# dm646x_cslr_vpif register map
Vendor: Texas Instruments
Peripheral module from a debugger description file.
Registers are 32-bit, access not given, reset 0x0 unless marked. A register's access mark holds for its fields unless they carry their own. Offsets are as the file gives them; lines under a group give offsets from that group; [hi:lo] are bit positions; {n}, {i} and the like mark numbered series; 'fields as' and 'values as' point back to an identical list; <NAME> marks a mode.

## VPIF
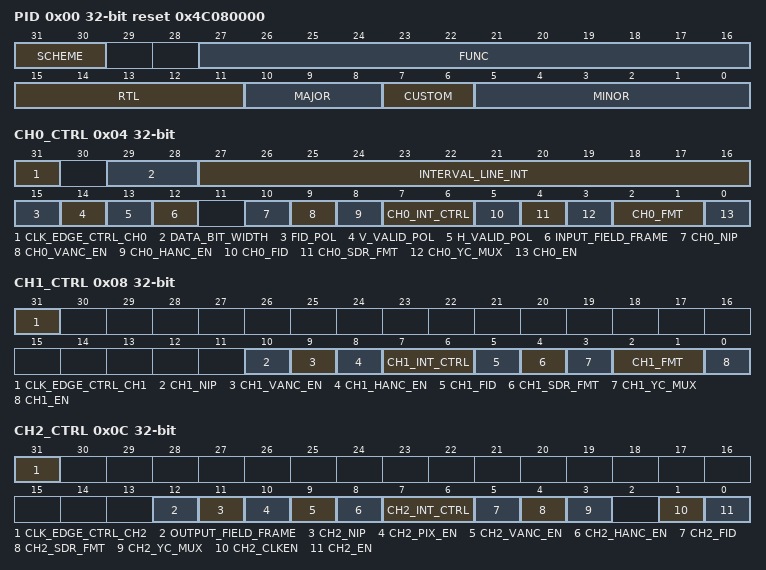
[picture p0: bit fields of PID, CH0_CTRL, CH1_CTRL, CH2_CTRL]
0x00 PID reset 0x4C080000 — VPIF Identification
  [31:30] SCHEME ro — Used to distinguish between old scheme and current. Spare bit to encode future schemes. Fixed to be "01"
  [27:16] FUNC ro — Function indicates an S/W compatible module family. If there is not level of S/W compatibility, a new Func number (and hence PID) should be assigned
  [15:11] RTL ro — Indicates RTL version
  [10:8] MAJOR ro — Local revision number which should be owned by module designer. This number should be updated for each major design change (such as bug fix, and memory size change etc ). In present design, fixed to be 0
  [7:6] CUSTOM ro — Indicates a special version for a particular device. Consequence of use may avoid use of standard chip support library (CSL). In this module, fixed to be 0.
  [5:0] MINOR ro — Local revision number which should be owned by module designer. This number should be updated for each small design change. In present design, fixed to be 0.
0x04 CH0_CTRL — Channel#0 control register
  [31] CLK_EDGE_CTRL_CH0 rw — This register defines timing relationship between data phase and clock edge for video input data which is connected to VPIF channel 0 (at the chip-pin level). Edge control is carried out outside the module (just register signal is only asserted from the module) 0: data phase is changed at rising edge of the input clock 1: data phase is changed at falling edge of the input clock
    0=RISE_EDGE (data phase is changed at rising edge of the input clock); 1=FALL_EDGE (data phase is changed at falling edge of the input clock)
  [29:28] DATA_BIT_WIDTH rw — Data bit width 00: 8 bit/pixel 01: 10 bit/pixel 10: 12 bit/pixel
  [27:16] INTERVAL_LINE_INT rw — Line interrrupt interval
  [15] FID_POL rw — Field ID polarity
    0=NOINVERT (No inversion); 1=INVERT (Invert incoming field ID signal inside the module)
  [14] V_VALID_POL rw — Vertical pixel valid signal polarity control
    0=NOINVERT (No inversion); 1=INVERT (Invert incoming "vertical pixel valid" signal inside the module)
  [13] H_VALID_POL rw — Horizontal pixel valid signal polarity control
    0=NOINVERT (No inversion); 1=INVERT (Invert incoming "horizontal pixel valid" signal inside the module)
  [12] INPUT_FIELD_FRAME rw — SDRAM storage mode of input picture
    0=FIELD (Field storage); 1=FRAME (Frame storage)
  [10] CH0_NIP rw — Output display format
    0=INTERLACED (Interlaced, 60 field/sec); 1=PROGRESS (Progressive, 30 frame/sec)
  [9] CH0_VANC_EN rw — Channel#0 Vertical Ancillary data enable 0:Vertical ancillary Data not supported 1:Vertical ancillary data is supported
    0=CH0_VRT_DIS (Vertical ancillary data disable); 1=CH0_VRT_EN (Vertical ancillary data enable)
  [8] CH0_HANC_EN rw — Channel#0 Horizontal Ancillary data enable 0: Horizontal ancillary Data not supported 1:Horizontal ancillary data is supported
    0=CH0_HZN_DIS (Horizontal ancillary data disable); 1=CH0_HZN_EN (Horizontal ancillary data enable)
  [7:6] CH0_INT_CTRL rw — Channel#0 Frame level interrupt to CPU 00: top field V-sync only 01: bottom field V-sync only 10: both top and bottom field V-sync 11: Reserved
  [5] CH0_FID ro — Channel#0 Field Identification
  [4] CH0_SDR_FMT rw — SDRAM address format control register 0: raster scanning mode 1: sub-picture mode
    0=CH0_RAS (Channel#0 Raster mode); 1=CH0_SP (Channel#0 sub-picture mode)
  [3] CH0_YC_MUX rw — Channel#0 input data format 0: Y/C non-multiplexed mode 1: Y/C multiplexed mode
    0=CH0_NON_YC (Channel#0 Non-multiplexed Y/C); 1=CH0_YC (Channel#0 Y/C multiplexed)
  [2:1] CH0_FMT rw — Channel#0 data mode to be processed 0x: BT. video (Y/C format) capture mode (sync signal is multiplexed). 1x: CCD/CMOS data capture mode (sync signal is independently prepared).
    0=BT_VIDEO_0 (BT. video (Y/C format) capture mode); 1=BT_VIDEO_1 (BT. video (Y/C format) capture mode); 2=CCD_CMOS_0 (CCD/CMOS data capture mode); 3=CCD_CMOS_1 (CCD/CMOS data capture mode)
  [0] CH0_EN rw — Channel#0 VPIF enable 0: Channel#0 VPIF module inactivated 1: Channel#0 VPIF module activated
    0=CH0_DIS (Channel#0 disable); 1=CH0_EN (Channel#0 enable)
0x08 CH1_CTRL — Channel#1 control register
  [31] CLK_EDGE_CTRL_CH1 rw — This register defines timing relationship between data phase and clock edge for video input data which is connected to VPIF channel 1 (at the chip-pin level). Edge control is carried out outside the module (just register signal is only asserted from the module) 0: data phase is changed at rising edge of the input clock 1: data phase is changed at falling edge of the input clock
    values as CH0_CTRL.CLK_EDGE_CTRL_CH0
  [10] CH1_NIP rw — Output display format 0: Interlaced (60 [field/sec]) format. 1: Progressive (30 [frame/sec]) format.
    values as CH0_CTRL.CH0_NIP
  [9] CH1_VANC_EN rw — Channel#1 Vertical Ancillary data enable 0: Vertical Ancillary Data not supported 1: Vertical ancillary data is supported
    0=CH1_VRT_DIS (Vertical ancillary data disable); 1=CH1_VRT_EN (Veritical ancillary data enable)
  [8] CH1_HANC_EN rw — Channel#1 Horizontal Ancillary data enable 0: Horizontal ancillary Data not supported 1:Horizontal ancillary data is supported
    0=CH1_HZN_DIS (Horizontal ancillary data disable); 1=CH1_HZN_EN (Horizontal ancillary data enable)
  [7:6] CH1_INT_CTRL rw — Channel#1 Frame level interrupt to CPU 00: top field V-sync only 01: bottom field V-sync only 10: both top and bottom field V-sync 11: Reserved
  [5] CH1_FID ro — Channel#1 Field Identification
  [4] CH1_SDR_FMT rw — SDRAM address format control register 0: raster scanning mode 1: sub-picture mode
    0=CH1_RAS (Channel#1 Raster mode); 1=CH1_SP (Channel#1 sub-picture mode)
  [3] CH1_YC_MUX rw — Channel#1 input data format 0: Y/C non-multiplexed mode 1: Y/C multiplexed mode
    0=CH1_NON_YC (Channel#1 Non-multiplexed Y/C); 1=CH1_YC (Channel#1 Y/C multiplexed)
  [2:1] CH1_FMT rw — Channel#1 data mode to be processed 0x: BT. video (Y/C format) capture mode (sync signal is multiplexed). 1x: CCD/CMOS data capture mode (sync signal is independently prepared).
    values as CH0_CTRL.CH0_FMT
  [0] CH1_EN rw — Channel#1 VPIF enable 0: Channel#1 VPIF module inactivated 1: Channel#1 VPIF module activated
    0=CH1_DIS (Channel#1 disable); 1=CH1_EN (Channel#1 enable)
0x0C CH2_CTRL — Channel#2 control register
  [31] CLK_EDGE_CTRL_CH2 rw — This register defines timing relationship between data phase and clock edge for video output data which is connected to VPIF channel 2 (at the chip-pin level). Edge control is carried out outside the module (just register signal is only asserted from the module) 0: data phase is changed at rising edge of the input clock 1: data phase is changed at falling edge of the input clock
    values as CH0_CTRL.CLK_EDGE_CTRL_CH0
  [12] OUTPUT_FIELD_FRAME rw — SDRAM storage mode of output picture 0: field independently stored. 1: frame based.
    0=FIELD (Field storage); 1=FRAME (Frame storage)
  [11] CH2_NIP rw — Output display format 0: Interlaced (60 [field/sec]) format. 1: Progressive (30 [frame/sec]) format.
    values as CH0_CTRL.CH0_NIP
  [10] CH2_PIX_EN rw — Pixel data enable or disable 0: Pixel data disabled 1: Pixel data enabled
    0=PIX_DIS (Pixel data disabled); 1=PIX_EN (Pixel data enabled)
  [9] CH2_VANC_EN rw — Channel#2 Vertical Ancillary data enable 0: Vertical Ancillary Data not supported 1: Vertical ancillary data is supported
    0=CH2_VRT_DIS (Vertical ancillary data disable); 1=CH2_VRT_EN (Veritical ancillary data enable)
  [8] CH2_HANC_EN rw — Channel#2 Horizontal Ancillary data enable 0: Horizontal ancillary Data not supported 1:Horizontal ancillary data is supported
    0=CH2_HZN_DIS (Horizontal ancillary data disable); 1=CH2_HZN_EN (Horizontal ancillary data enable)
  [7:6] CH2_INT_CTRL rw — Channel#2 Frame level interrupt to CPU 00: top field V-sync only 01: bottom field V-sync only 10: both top and bottom field V-sync 11: Reserved
  [5] CH2_FID ro — Channel#2 Field Identification
  [4] CH2_SDR_FMT rw — SDRAM address format control register 0: raster scanning mode 1: sub-picture mode
    0=CH2_RAS (Channel#2 Raster mode); 1=CH2_SP (Channel#2 sub-picture mode)
  [3] CH2_YC_MUX rw — Channel#2 data format to be transmitted 0: Y/C non-multiplexed mode 1: Y/C multiplexed mode
    0=CH2_NON_YC (Y/C non-multiplexed mode); 1=CH2_YC_MUX (Y/C multiplexed mode)
  [1] CH2_CLKEN rw — Channel#2 VPIF Clock enable 0: Channel#2 clock inactivated 1: Channel#2 clock activated
    0=CH2_CLKDIS (Channel#2 clock disable); 1=CH2_CLKEN (Channel#2 clock enable)
  [0] CH2_EN rw — Channel#2 VPIF enable 0: Channel#2 VPIF module inactivated 1: Channel#2 VPIF module activated
    0=CH2_DIS (Channel#2 disable); 1=CH2_EN (Channel#2 enable)
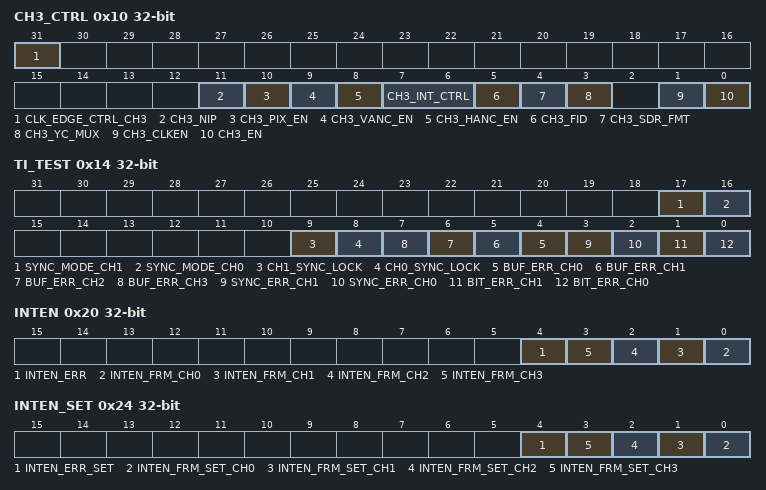
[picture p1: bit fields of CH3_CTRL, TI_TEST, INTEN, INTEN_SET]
0x10 CH3_CTRL — Channel#3 control register
  [31] CLK_EDGE_CTRL_CH3 rw — This register defines timing relationship between data phase and clock edge for video output data which is connected to VPIF channel 3 (at the chip-pin level). Edge control is carried out outside the module (just register signal is only asserted from the module) 0: data phase is changed at rising edge of the input clock 1: data phase is changed at falling edge of the input clock
    values as CH0_CTRL.CLK_EDGE_CTRL_CH0
  [11] CH3_NIP rw — Output display format 0: Interlaced (60 [field/sec]) format. 1: Progressive (30 [frame/sec]) format.
    values as CH0_CTRL.CH0_NIP
  [10] CH3_PIX_EN rw — Pixel data enable or disable 0: Pixel data disabled 1: Pixel data enabled
    values as CH2_CTRL.CH2_PIX_EN
  [9] CH3_VANC_EN rw — Channel#3 Vertical Ancillary data enable 0: Vertical Ancillary Data not supported 1: Vertical ancillary data is supported
    0=CH3_VRT_DIS (Vertical ancillary data disable); 1=CH3_VRT_EN (Veritical ancillary data enable)
  [8] CH3_HANC_EN rw — Channel#3 Horizontal Ancillary data enable 0: Horizontal ancillary Data not supported 1:Horizontal ancillary data is supported
    0=CH3_HZN_DIS (Horizontal ancillary data disable); 1=CH3_HZN_EN (Horizontal ancillary data enable)
  [7:6] CH3_INT_CTRL rw — Channel#3 Frame level interrupt to CPU 00: top field V-sync only 01: bottom field V-sync only 10: both top and bottom field V-sync 11: Reserved
  [5] CH3_FID ro — Channel#3 Field Identification
  [4] CH3_SDR_FMT rw — SDRAM address format control register 0: raster scanning mode 1: sub-picture mode
    0=CH3_RAS (Channel#3 Raster mode); 1=CH3_SP (Channel#3 sub-picture mode)
  [3] CH3_YC_MUX rw — Channel#3 data format to be transmitted 0: Y/C non-multiplexed mode 1: Y/C multiplexed mode
    0=CH3_NON_YC (Y/C non-multiplexed mode); 1=CH3_YC_MUX (Y/C multiplexed mode)
  [1] CH3_CLKEN rw — Channel#3 VPIF Clock enable 0: Channel#3 clock inactivated 1: Channel#3 clock activated
    0=CH3_CLKDIS (Channel#3 clock disable); 1=CH3_CLKEN (Channel#3 clock enable)
  [0] CH3_EN rw — Channel#3 VPIF enable 0: Channel#3 VPIF module inactivated 1: Channel#3 VPIF module activated
    0=CH3_DIS (Channel#3 disable); 1=CH3_EN (Channel#3 enable)
0x14 TI_TEST — Used for TI internal testing
  [17] SYNC_MODE_CH1 rw — Synchronization mode on VPIF channel 1 0: free mode (searching header code consists of "FF-00-00-SAV (EAV)" 1: hold mode (driven by internal counter)
    0=SYNC_FREE (free mode); 1=SYNC_HOLD (hold mode)
  [16] SYNC_MODE_CH0 rw — Synchronization mode on VPIF channel 0 0: free mode (searching header code consists of "FF-00-00-SAV (EAV)" 1: hold mode (driven by internal counter)
    0=SYNC_FREE (free mode); 1=SYNC_HOLD (hold mode)
  [9] CH1_SYNC_LOCK ro — VPIF channel#1 synchronize status 0: Channel-1 not synchronized 1: Channel-1 synchronized
    0=CH1_NO_SYNC (Ch#1 not synchronized); 1=CH1_SYNC (Ch#1 synchronized)
  [8] CH0_SYNC_LOCK ro — VPIF channel#0 synchronize status 0: Channel-0 not synchronized 1: Channel-0 synchronized
    0=CH0_NO_SYNC (Ch#0 not synchronized); 1=CH0_SYNC (Ch#0 synchronized)
  [n+4] BUF_ERR_CH{n} ro (n=0..3) — VPIF channel {n} status register indicating existence of buffer overflow or underflow 0: buffer overflow/underflow error doesn't exist. 1: buffer overflow/underflow error exists.
    0=NO_BUF_ERR (buffer overflow/underflow error doesn't exist); 1=BUF_ERR (buffer overflow/underflow error exist)
  [3] SYNC_ERR_CH1 ro — Channel 1 status register indicating existence of error sync distance between SAV and EAV 0: Sync distance error doesn't exist 1: Sync distance error exists
    0=NO_SYNC_ERR (Sync distance error doesn't exist); 1=SYNC_ERR (Sync distance error exist)
  [2] SYNC_ERR_CH0 ro — Channel 0 status register indicating existence of error sync distance between SAV and EAV 0: Sync distance error doesn't exist 1: Sync distance error exists
    values as SYNC_ERR_CH1
  [1] BIT_ERR_CH1 ro — status register indicating existence of error bit on SAV and EAV signal for VPIF channel 1 0: SAV/EAV bit error doesn't exists 1: SAV/EAV bit error exists
    0=NO_BIT_ERR (No EAV/SAV bit error); 1=BIT_ERR (EAV/SAV bit error exist)
  [0] BIT_ERR_CH0 ro — status register indicating existence of error bit on SAV and EAV signal for VPIF channel 0 0: SAV/EAV bit error doesn't exists 1: SAV/EAV bit error exists
    values as BIT_ERR_CH1
0x20 INTEN — Interrupt enable register
  [4] INTEN_ERR rw — To activate error interrupt 0: Error interrupt disabled 1: Error interrupt enabled
    0=INT_ERR_DIS (Error interrupt disable); 1=INT_ERR_EN (Error interrupt enabled)
  [n] INTEN_FRM_CH{n} rw (n=0..3) — Frame interrupt enable for Channel#{n} 0: Channel#{n} Frame interrupt disable 1: Channel#{n} Frame interrupt enable
    0=INT_CH{n}FRM_DIS (Channel#{n} frame interrupt disable); 1=INT_CH{n}FRM_EN (Channel#{n} frame interrupt enable)
0x24 INTEN_SET — Interrupt activation register
  [4] INTEN_ERR_SET rw — To activate error interrupt 0: Error interrupt disabled 1: Error interrupt enabled
    0=INT_ERR_SET_D (vpif_inten_error inactivated); 1=INT_ERR_SET_E (vpif_inten_error activated)
  [n] INTEN_FRM_SET_CH{n} rw (n=0..3) — Frame interrupt enable for Channel#{n} 0: Channel#{n} Frame interrupt disable 1: Channel#{n} Frame interrupt enable
    0=I_CH{n}FRMSET_D (vpif_inten_frame_ch{n} inactivated); 1=I_CH{n}FRMSET_E (vpif_inten_frame_ch{n} activated)
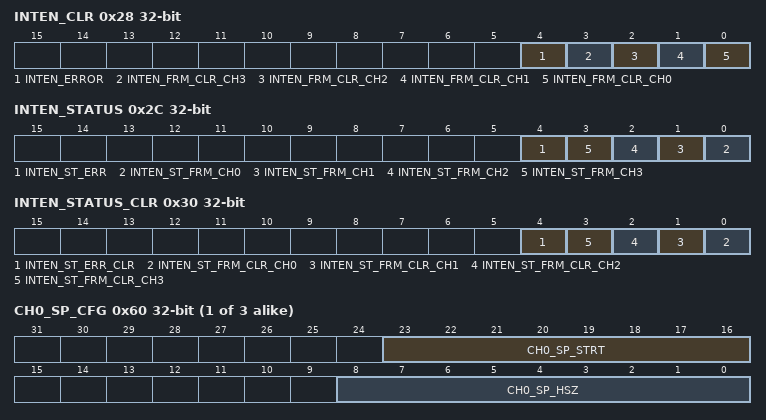
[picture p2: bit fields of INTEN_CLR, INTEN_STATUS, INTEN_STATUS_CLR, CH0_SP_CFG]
0x28 INTEN_CLR — Interrupt clear register
  [4] INTEN_ERROR wo — To activate error interrupt 0: No change 1: Interrupt on vpif_inten_error inactivated
    0=NC (No change); 1=INT_ERR_DIS (vpif_inten_error inactivated)
  [3] INTEN_FRM_CLR_CH3 wo — Frame interrupt enable for Channel#3 0: NC 1: Interrupt on vpif_inten_frame_ch3 inactivated
    0=NC (No change); 1=I_CH3FRM_DIS (vpif_inten_frame_ch3 inactivated)
  [2] INTEN_FRM_CLR_CH2 wo — Frame interrupt enable for Channel#2 0: NC 1: Channel#2 Frame interrupt enable
    0=NC (No change); 1=I_CH2FRM_DIS (vpif_inten_frame_ch2 inactivated)
  [1] INTEN_FRM_CLR_CH1 wo — Frame interrupt enable for Channel#1 0: NC 1: Channel#1 Frame interrupt enable
    0=NC (No change); 1=I_CH1FRM_DIS (vpif_inten_frame_ch1 inactivated)
  [0] INTEN_FRM_CLR_CH0 wo — Frame interrupt enable for Channel#0 0: NC 1: Channel#0 Frame interrupt enable
    0=NC (No change); 1=I_CH0FRM_DIS (vpif_inten_frame_ch0 inactivated)
0x2C INTEN_STATUS — Interrupt Status register
  [4] INTEN_ST_ERR ro — Error interrupt status 0: Error is not detected so far 1: Error is detected and not checked yet
    0=NO_ERR (Error not detected); 1=ERR_DET (Error detected)
  [n] INTEN_ST_FRM_CH{n} ro (n=0..3) — Frame sync detect for Channel#{n} 0: Channel#{n} Frame sync not detected 1: Channel#{n} Frame sync detected
    0=NO_CH{n}_FRM (Channel#{n} frame sync not detected); 1=CH{n}_FRM_DET (Channel#{n} frame sync detected)
0x30 INTEN_STATUS_CLR — Interrupt Status clear register
  [4] INTEN_ST_ERR_CLR wo — Status clear register 0: No Change 1: VPIF status clear resiger
    0=NC (No change); 1=CLR (vpif_status clear register)
  [n] INTEN_ST_FRM_CLR_CH{n} wo (n=0..3) — Channel#{n} status clear register 0: No change 1: Channel#{n} status clear register
    0=CH{n}_NC (Channel#{n} No change); 1=CH{n}_CLR (Channel#{n} clear register)
0x34 EMUL_CTL — Emulation suspend control register
  [0] EMULSUSP_FREE rw — Peripheral respond to emulation suspend signal control 0: Emulation control based on vpif_emulsusp_soft 1: Emulation configuration ignore
    0=EM_ACT (Emulation control activated); 1=EM_IGN (Emulation control ignore)
0x38 REQ_SIZE — VPIF DMA request unit size control register
  [8:0] REQ_SIZE rw — DMA request unit size 000100000: 32 byte 001000000: 64 byte 010000000: 128 byte 100000000: 256 byte
{0x40+0x40*i} CH{i}_TOP_STRT_LUMA rw (i=0..2) — Channel#{i} top start add register for luma
  [31:0] CH{i}_TOP_STRT_LUMA — Defines Channel#{i} top start address for luma
0x44 CH0_BTM_STRT_LUMA rw — Channel#0 btm start add register for luma
  [31:0] CH0_BTM_STRT_LUMA — Defines Channel#0 btm start address for luma
{0x48+0x40*i} CH{i}_TOP_STRT_CHROMA rw (i=0..2) — Channel#{i} top start add register for chroma
  [31:0] CH{i}_TOP_STRT_CHROMA — Defines Channel#{i} top start address for chroma
{0x4C+0x40*i} CH{i}_BTM_STRT_CHROMA rw (i=0..2) — Channel#{i} btm start add register for chroma
  [31:0] CH{i}_BTM_STRT_CHROMA — Defines Channel#{i} btm start address for chroma
{0x50+0x40*i} CH{i}_TOP_STRT_HANC rw (i=0..2) — Channel#{i} top start add register for hanc
  [31:0] CH{i}_TOP_STRT_HANC — Defines Channel#{i} top start address for hanc
0x54 CH0_BTM_STRT_HANC rw — Channel#0 btm start add register for hanc
  [31:0] CH0_BTM_STRT_HANC — Defines Channel#0 btm start address for hanc
{0x58+0x40*i} CH{i}_TOP_STRT_VANC rw (i=0..2) — Channel#{i} top start add register for vanc
  [31:0] CH{i}_TOP_STRT_VANC — Defines Channel#{i} top start address for vanc
{0x5C+0x40*i} CH{i}_BTM_STRT_VANC rw (i=0..2) — Channel#{i} btm start add register for vanc
  [31:0] CH{i}_BTM_STRT_VANC — Defines Channel#{i} btm start address for vanc
{0x60+0x40*i} CH{i}_SP_CFG (i=0..2) — Channel#{i} sub-picture configuration
  [23:16] CH{i}_SP_STRT rw — Channel#{i} horizontal start position
  [8:0] CH{i}_SP_HSZ rw — Sub-picture horizontal size 000010000: 16 byte 000100000: 32 byte 001000000: 64 byte 010000000: 128 byte 100000000: 256 byte
{0x64+0x40*i} CH{i}_IMG_ADD_OFST rw (i=0..2) — Channel#{i} image offset address
{0x68+0x40*i} CH{i}_HANC_ADD_OFST rw (i=0..2) — Channel#{i} hanc offset address
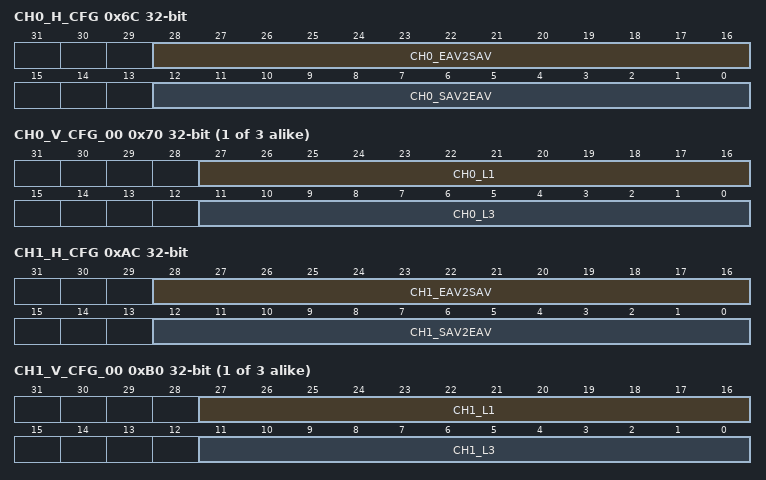
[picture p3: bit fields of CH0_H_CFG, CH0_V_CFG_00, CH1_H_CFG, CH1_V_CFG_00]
0x6C CH0_H_CFG — Channel#0 horizontal configuration
  [28:16] CH0_EAV2SAV rw — Distance between EAV to SAV
  [12:0] CH0_SAV2EAV rw — Distance between SAV to EAV
{0x70+4i} CH0_V_CFG_{i:02} (i=0..2) — Channel#0 vertical data size configuration {i}
  [27:16] CH0_L{4i+1} rw — L{4i+1} register configuraion
  [11:0] CH0_L{4i+3} rw — L{4i+3} register configuration
0x7C CH0_V_SIZE — Channel#0 vertical image size of incoming video data
  [11:0] CH0_VSZ rw — Vertical image size
0x84 CH1_BTM_STRT_LUMA rw — Channel#1 btm start add register for luma
  [31:0] CH1_BTM_STRT_LUMA — Defines Channel#1 btm start address for luma
0x94 CH1_BTM_STRT_HANC rw — Channel#0 btm start add register for hanc
  [31:0] CH1_BTM_STRT_HANC — Defines Channel#1 btm start address for hanc
0xAC CH1_H_CFG — Channel#1 horizontal configuration
  [28:16] CH1_EAV2SAV rw — Distance between EAV to SAV
  [12:0] CH1_SAV2EAV rw — Distance between SAV to EAV
{0xB0+4i} CH1_V_CFG_{i:02} (i=0..2) — Channel#1 vertical data size configuration {i}
  [27:16] CH1_L{4i+1} rw — L{4i+1} register configuraion
  [11:0] CH1_L{4i+3} rw — L{4i+3} register configuration
0xBC CH1_V_SIZE — Channel#1 vertical image size
  [11:0] CH1_VSZ rw — Vertical image size
0xC4 CH2_BTM_STRT_LUMA rw — Channel#1 btm start add register for luma
  [31:0] CH2_BTM_STRT_LUMA — Defines Channel#2 btm start address for luma
0xD4 CH2_BTM_STRT_HANC rw — Channel#2 btm start add register for hanc
  [31:0] CH2_BTM_STRT_HANC — Defines Channel#2 btm start address for hanc
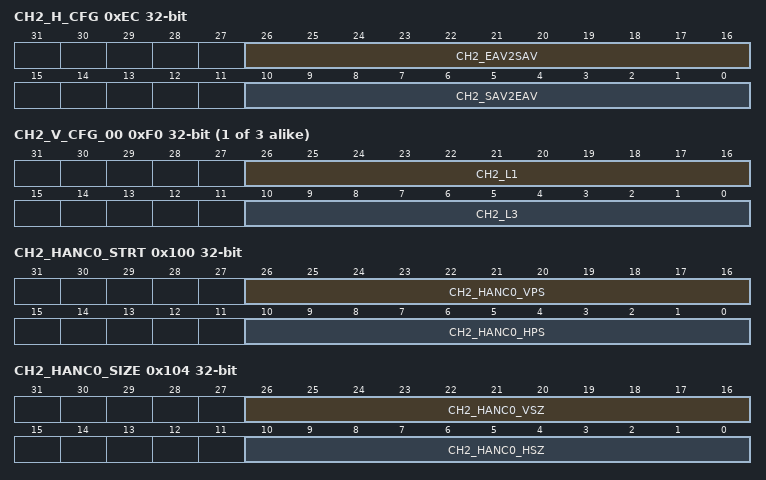
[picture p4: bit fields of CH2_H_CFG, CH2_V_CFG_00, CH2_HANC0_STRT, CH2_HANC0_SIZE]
0xEC CH2_H_CFG — Channel#2 horizontal configuration
  [26:16] CH2_EAV2SAV rw — Distance between EAV to SAV
  [10:0] CH2_SAV2EAV rw — Distance between SAV to EAV
{0xF0+4i} CH2_V_CFG_{i:02} (i=0..2) — Channel#2 vertical data size configuration {i}
  [26:16] CH2_L{4i+1} rw — L{4i+1} register configuraion
  [10:0] CH2_L{4i+3} rw — L{4i+3} register configuration
0xFC CH2_V_SIZE — Channel#2 vertical image size
  [10:0] CH2_VSZ rw — Vertical image size of incoming video data
0x100 CH2_HANC0_STRT — Channel#2 Horizontal ancillary data insertion top start position
  [26:16] CH2_HANC0_VPS rw — Channel#2 veritical start position for hanc0
  [10:0] CH2_HANC0_HPS rw — Channel#2 horizontal start position for hanc0
0x104 CH2_HANC0_SIZE — Channel#2 Horizontal ancillary data top size
  [26:16] CH2_HANC0_VSZ rw — Channel#2 hanc0 vertical size
  [10:0] CH2_HANC0_HSZ rw — Channel#2 hanc0 horizontal size
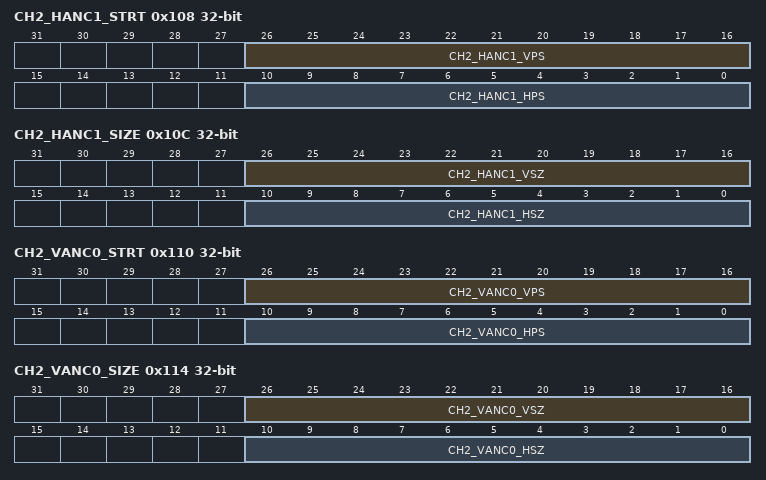
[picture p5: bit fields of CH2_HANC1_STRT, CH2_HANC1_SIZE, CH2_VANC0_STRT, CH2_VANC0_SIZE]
0x108 CH2_HANC1_STRT — Channel#2 Horizontal ancillary data insertion btm start position
  [26:16] CH2_HANC1_VPS rw — Channel#2 veritical start position for hanc1
  [10:0] CH2_HANC1_HPS rw — Channel#2 horizontal start position for hanc1
0x10C CH2_HANC1_SIZE — Channel#2 Horizontal ancillary data btm size
  [26:16] CH2_HANC1_VSZ rw — Channel#2 hanc1 vertical size
  [10:0] CH2_HANC1_HSZ rw — Channel#2 hanc1 horizontal size
0x110 CH2_VANC0_STRT — Channel#2 Vertical ancillary data insertion top start position
  [26:16] CH2_VANC0_VPS rw — Channel#2 veritical start position for vanc0
  [10:0] CH2_VANC0_HPS rw — Channel#2 horizontal start position for vanc0
0x114 CH2_VANC0_SIZE — Channel#2 Vertical ancillary data top size
  [26:16] CH2_VANC0_VSZ rw — Channel#2 vanc0 vertical size
  [10:0] CH2_VANC0_HSZ rw — Channel#2 vanc0 horizontal size
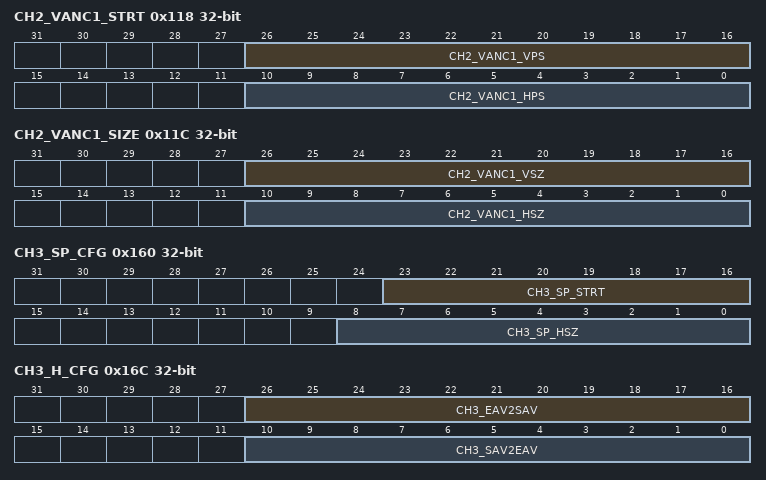
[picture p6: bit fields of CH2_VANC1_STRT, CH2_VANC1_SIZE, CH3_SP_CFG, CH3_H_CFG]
0x118 CH2_VANC1_STRT — Channel#2 Vertical ancillary data insertion btm start position
  [26:16] CH2_VANC1_VPS rw — Channel#2 veritical start position for vanc1
  [10:0] CH2_VANC1_HPS rw — Channel#2 vertical start position for vanc1
0x11C CH2_VANC1_SIZE — Channel#2 Vertical ancillary data btm size
  [26:16] CH2_VANC1_VSZ rw — Channel#2 vanc1 vertical size
  [10:0] CH2_VANC1_HSZ rw — Channel#2 vanc1 horizontal size
0x140 CH3_TOP_STRT_LUMA rw — Channel#3 top start add register for luma
  [31:0] CH3_TOP_STRT_LUMA — Defines Channel#3 top start address for luma
0x144 CH3_BTM_STRT_LUMA rw — Channel#3 btm start add register for luma
  [31:0] CH3_BTM_STRT_LUMA — Defines Channel#3 btm start address for luma
0x148 CH3_TOP_STRT_CHROMA rw — Channel#3 top start add register for chroma
  [31:0] CH3_TOP_STRT_CHROMA — Defines Channel#3 top start address for chroma
0x14C CH3_BTM_STRT_CHROMA rw — Channel#3 btm start add register for chroma
  [31:0] CH3_BTM_STRT_CHROMA — Defines Channel#3 btm start address for chroma
0x150 CH3_TOP_STRT_HANC rw — Channel#3 top start add register for hanc
  [31:0] CH3_TOP_STRT_HANC — Defines Channel#3 top start address for hanc
0x154 CH3_BTM_STRT_HANC rw — Channel#3 btm start add register for hanc
  [31:0] CH3_BTM_STRT_HANC — Defines Channel#3 btm start address for hanc
0x158 CH3_TOP_STRT_VANC rw — Channel#3 top start add register for vanc
  [31:0] CH3_TOP_STRT_VANC — Defines Channel#3 top start address for vanc
0x15C CH3_BTM_STRT_VANC rw — Channel#3 btm start add register for vanc
  [31:0] CH3_BTM_STRT_VANC — Defines Channel#3 btm start address for vanc
0x160 CH3_SP_CFG — Channel#3 sub-picture configuration
  [23:16] CH3_SP_STRT rw — Channel#3 horizontal start position
  [8:0] CH3_SP_HSZ rw — Sub-picture horizontal size 000010000: 16 byte 000100000: 32 byte 001000000: 64 byte 010000000: 128 byte 100000000: 256 byte
0x164 CH3_IMG_ADD_OFST rw — Channel#3 image offset address
0x168 CH3_HANC_ADD_OFST rw — Channel#3 hanc offset address
0x16C CH3_H_CFG — Channel#3 horizontal configuration
  [26:16] CH3_EAV2SAV rw — Distance between EAV to SAV
  [10:0] CH3_SAV2EAV rw — Distance between SAV to EAV
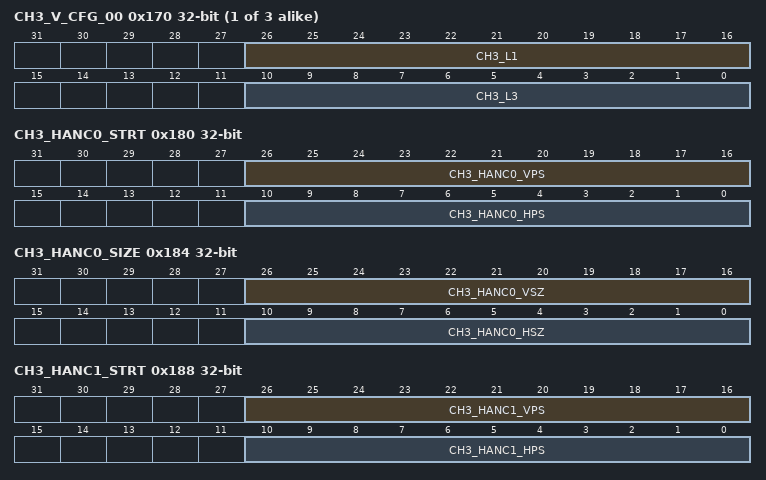
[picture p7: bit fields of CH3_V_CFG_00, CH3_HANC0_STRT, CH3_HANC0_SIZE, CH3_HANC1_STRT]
{0x170+4i} CH3_V_CFG_{i:02} (i=0..2) — Channel#3 vertical data size configuration {i}
  [26:16] CH3_L{4i+1} rw — L{4i+1} register configuraion
  [10:0] CH3_L{4i+3} rw — L{4i+3} register configuration
0x17C CH3_V_SIZE — Channel#3 vertical Image size
  [10:0] CH3_VSZ rw — L12 register configuraion
0x180 CH3_HANC0_STRT — Channel#3 Horizontal ancillary data insertion top start position
  [26:16] CH3_HANC0_VPS rw — Channel#3 veritical start position for hanc0
  [10:0] CH3_HANC0_HPS rw — Channel#3 horizontal start position for hanc0
0x184 CH3_HANC0_SIZE — Channel#3 Horizontal ancillary data top size
  [26:16] CH3_HANC0_VSZ rw — Channel#3 hanc0 vertical size
  [10:0] CH3_HANC0_HSZ rw — Channel#3 hanc0 horizontal size
0x188 CH3_HANC1_STRT — Channel#3 Horizontal ancillary data insertion btm start position
  [26:16] CH3_HANC1_VPS rw — Channel#3 veritical start position for hanc1
  [10:0] CH3_HANC1_HPS rw — Channel#3 horizontal start position for hanc1
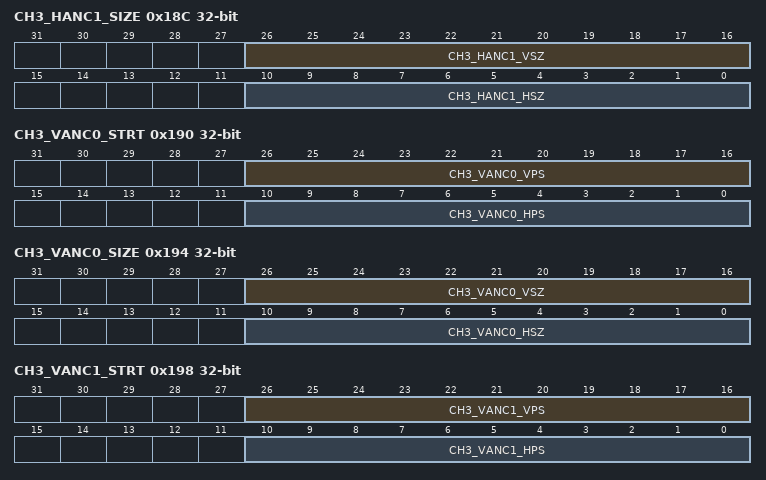
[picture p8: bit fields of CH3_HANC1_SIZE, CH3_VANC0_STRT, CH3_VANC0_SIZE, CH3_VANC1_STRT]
0x18C CH3_HANC1_SIZE — Channel#3 Horizontal ancillary data btm size
  [26:16] CH3_HANC1_VSZ rw — Channel#3 hanc1 vertical size
  [10:0] CH3_HANC1_HSZ rw — Channel#3 hanc1 horizontal size
0x190 CH3_VANC0_STRT — Channel#3 Vertical ancillary data insertion top start position
  [26:16] CH3_VANC0_VPS rw — Channel#3 veritical start position for vanc0
  [10:0] CH3_VANC0_HPS rw — Channel#3 horizontal start position for vanc0
0x194 CH3_VANC0_SIZE — Channel#3 Vertical ancillary data top size
  [26:16] CH3_VANC0_VSZ rw — Channel#3 vanc0 vertical size
  [10:0] CH3_VANC0_HSZ rw — Channel#3 vanc0 horizontal size
0x198 CH3_VANC1_STRT — Channel#3 Vertical ancillary data insertion btm start position
  [26:16] CH3_VANC1_VPS rw — Channel#3 veritical start position for vanc1
  [10:0] CH3_VANC1_HPS rw — Channel#3 vertical start position for vanc1
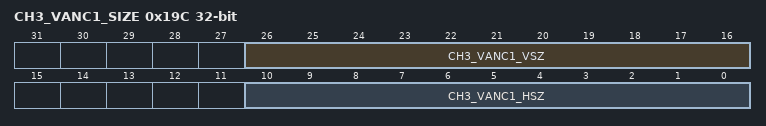
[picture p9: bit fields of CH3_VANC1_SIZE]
0x19C CH3_VANC1_SIZE — Channel#3 Vertical ancillary data btm size
  [26:16] CH3_VANC1_VSZ rw — Channel#3 vanc1 vertical size
  [10:0] CH3_VANC1_HSZ rw — Channel#3 vanc1 horizontal size
0x1C0 IODFT_CTRL — IODFT control register
  [2:0] IODFT_CTRL rw — IODFT control bits 000: Normal function mode 001: Reserved 010: Reserved 011: Reserved 100: Loop Back with PAD 101: Internal loop back 110: Input buffer test 111: Reserved
